# WKUP_CTRL_MMR0_CFG0 register map
Vendor: Texas Instruments
Registers are 32-bit, read-write, reset 0x0 unless marked. A register's access mark holds for its fields unless they carry their own. Offsets are as the file gives them; [hi:lo] are bit positions; {n}, {i} and the like mark numbered series.

## WKUP_CTRL_MMR0_CFG0 (part 2 of 11)
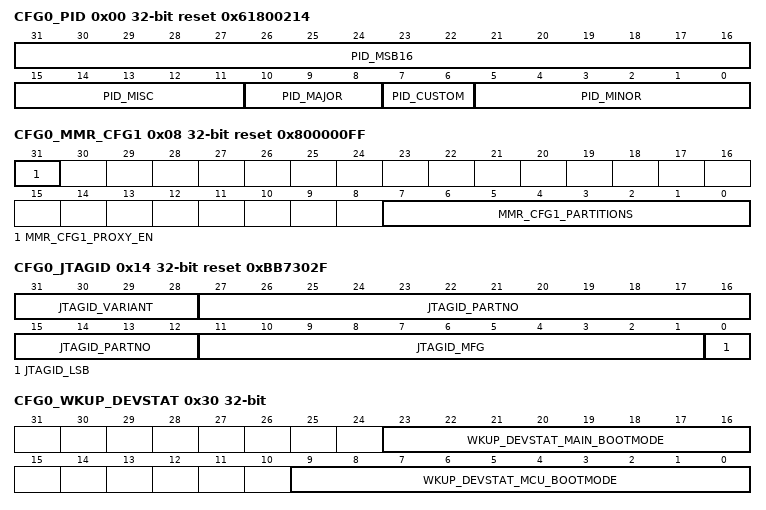
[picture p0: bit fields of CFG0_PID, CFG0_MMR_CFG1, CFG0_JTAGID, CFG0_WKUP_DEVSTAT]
0x00 CFG0_PID ro reset 0x61800214 — Peripheral release details
  [31:16] PID_MSB16
  [15:11] PID_MISC
  [10:8] PID_MAJOR
  [7:6] PID_CUSTOM — Custom revision number - actual value determined by RTL
  [5:0] PID_MINOR
0x08 CFG0_MMR_CFG1 ro reset 0x800000FF — Indicates the MMR configuration
  [31] MMR_CFG1_PROXY_EN — Proxy addressing enabled
  [7:0] MMR_CFG1_PARTITIONS — Indicates present partitions
0x14 CFG0_JTAGID ro reset 0xBB7302F — The JTAGID register must be readable by the configuration bus so that this can be accessed via the JTAG and CPU. In Boundary Scan mode, this ID should also be readable with only TCLK present. This means without a valid CPU clock running and also implies that Fusefarm scan is not necessary. The partno and variant field inputs should be set in the top metal mask so that this may be changed if a future PG is necessary. All other fields may be hard coded.
  [31:28] JTAGID_VARIANT — Used to indicate new PGs
  [27:12] JTAGID_PARTNO — Part number for boundary scan
  [11:1] JTAGID_MFG — Indicates manufacturer
  [0] JTAGID_LSB — Always 1
{0x20+4i} CFG0_DIE_ID{i} ro (i=0..3) — Contains information to identify this particular die.
  [31:0] DIE_ID{i}_DIEID — Contains individual die information
0x30 CFG0_WKUP_DEVSTAT — Indicates MCU bootstrap selection. The default value of this register is determined by the MCU bootstrap pins when the por_boot_cfg_srst_n input is de-asserted.
  [23:16] WKUP_DEVSTAT_MAIN_BOOTMODE — Specifies the device Primary and Backup boot media.Bit assignments defined by ROM
  [9:0] WKUP_DEVSTAT_MCU_BOOTMODE — Indicates MCU boot mode. Bits 9:8 - Power-on Self Test mode (if POST_SEL_STAT = 0x0) 00 - POST mode 1 (See POST_OPT_opt1_xxx bitfields) 01 - POST mode 2 (See POST_OPT_opt2_xxx bitfields) 10 - POST mode 3 (See POST_OPT_opt3_xxx bitfields) 11 - Bypass POST Bits 7:3 - MCU primary and secondary boot source Bits 2:0 - HFOSC0 frequency selection 000 - 19.2 MHz 001 - 20.0 MHz 010 - 24.0 MHz 011 - 25.0 MHz 100 - 26.0 MHz 101 - 27.0 MHz 110 - Reserved for device test 111 - No PLL configuration
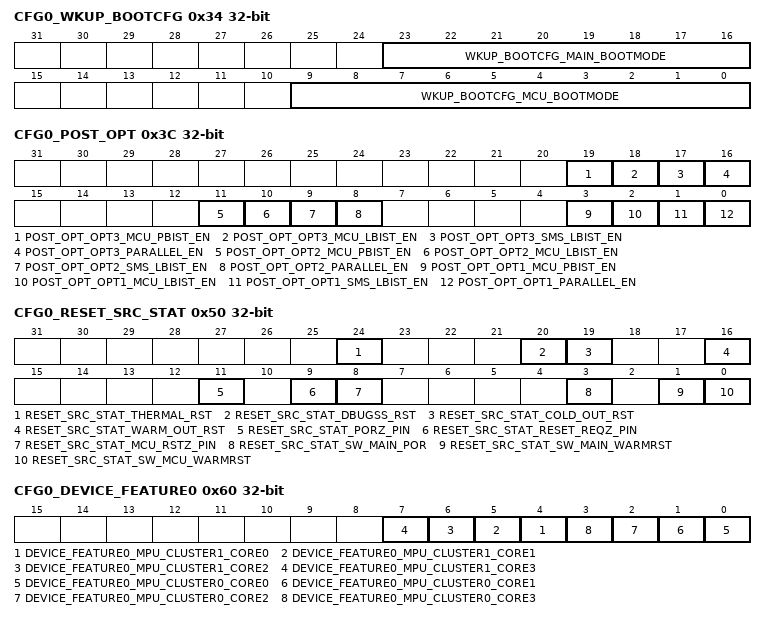
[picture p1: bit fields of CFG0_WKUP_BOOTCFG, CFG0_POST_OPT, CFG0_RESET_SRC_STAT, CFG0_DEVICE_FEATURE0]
0x34 CFG0_WKUP_BOOTCFG ro — Indicates MCU bootstrap selection latched at power-on reset by PORz. The default value of this register is determined by the MCU bootstrap pins when the por_boot_cfg_srst_n input is de-asserted and will remain until the MCU bootstrap pins are re-latched on a subsequent por_boot_cfg_srst_n rising edge.
  [23:16] WKUP_BOOTCFG_MAIN_BOOTMODE — Specifies the device Primary and Backup boot media as latched at PORzBit assignments assigned by ROM
  [9:0] WKUP_BOOTCFG_MCU_BOOTMODE — Indicates MCU boot mode as latched at power-on reset
0x38 CFG0_POST_SEL_STAT ro — Indicates which power-on self test option was performed.
  [1:0] POST_SEL_STAT_POST_SEL_STAT — Indicates which POST option was selected at power-up
0x3C CFG0_POST_OPT ro — Bits 19:16 - POST Option 3
  [19] POST_OPT_OPT3_MCU_PBIST_EN — MCU R5 PBIST enabled
  [18] POST_OPT_OPT3_MCU_LBIST_EN — MCU R5 LBIST enabled
  [17] POST_OPT_OPT3_SMS_LBIST_EN — SMS LBIST enabled
  [16] POST_OPT_OPT3_PARALLEL_EN — Selects SMS/MCU R5 LBIST sequencing 0 - Serial (SMS LBIST performed first) 1 - Parallel
  [11] POST_OPT_OPT2_MCU_PBIST_EN — MCU R5 PBIST enabled
  [10] POST_OPT_OPT2_MCU_LBIST_EN — MCU R5 LBIST enabled
  [9] POST_OPT_OPT2_SMS_LBIST_EN — SMS LBIST enabled
  [8] POST_OPT_OPT2_PARALLEL_EN — Selects SMS/MCU R5 LBIST sequencing 0 - Serial (SMS LBIST performed first) 1 - Parallel
  [3] POST_OPT_OPT1_MCU_PBIST_EN — MCU R5 PBIST enabled
  [2] POST_OPT_OPT1_MCU_LBIST_EN — MCU R5 LBIST enabled
  [1] POST_OPT_OPT1_SMS_LBIST_EN — SMS LBIST enabled
  [0] POST_OPT_OPT1_PARALLEL_EN — Selects SMS/MCU R5 LBIST sequencing 0 - Serial (SMS LBIST performed first) 1 - Parallel
0x44 CFG0_BOOT_PROGRESS — Used by ROM to mark the progress of the boot operation
  [31:0] BOOT_PROGRESS_PROGRESS — Written by ROM to indicate boot progression. Values and their meaning are determined by the ROM.
0x50 CFG0_RESET_SRC_STAT — Indicates sosurce of last device reset
  [24] RESET_SRC_STAT_THERMAL_RST — When set, indicates that a VTM Max Temp Thermal reset occurred.Write 1 to clear this bit.
  [20] RESET_SRC_STAT_DBUGSS_RST — When set, indicates that a Debug reset occurred.Write 1 to clear this bit.
  [19] RESET_SRC_STAT_COLD_OUT_RST — When set, indicates that a SMS Cold reset occurred.Write 1 to clear this bit.
  [16] RESET_SRC_STAT_WARM_OUT_RST — When set, indicates that a SMS Warm reset occurred.Write 1 to clear this bit.
  [11] RESET_SRC_STAT_PORZ_PIN — When set indicates that a PORz pin reset occurred.Write 1 to clear this bit.
  [9] RESET_SRC_STAT_RESET_REQZ_PIN — When set indicates that a RESET_REQz pin reset occurred.Write 1 to clear this bit.
  [8] RESET_SRC_STAT_MCU_RSTZ_PIN — When set indicates that a MCU_RESETz pin reset occurred.Write 1 to clear this bit.
  [3] RESET_SRC_STAT_SW_MAIN_POR — When set, indicates that a Software MAIN Power-on reset occurred.Write 1 to clear this bit.
  [1] RESET_SRC_STAT_SW_MAIN_WARMRST — When set indicates that a Software MAIN Warm reset occurred.Write 1 to clear this bit.
  [0] RESET_SRC_STAT_SW_MCU_WARMRST — When set indicates that a Software MCU Warm reset occurred.Write 1 to clear this bit.
0x60 CFG0_DEVICE_FEATURE0 ro — Indicates enabled MPU processing elements on the device
  [n+4] DEVICE_FEATURE0_MPU_CLUSTER1_CORE{n} (n=0..3) — MPU Cluster1 Core {n} is enabled when set
  [n] DEVICE_FEATURE0_MPU_CLUSTER0_CORE{n} (n=0..3) — MPU Cluster0 Core {n} is enabled when set
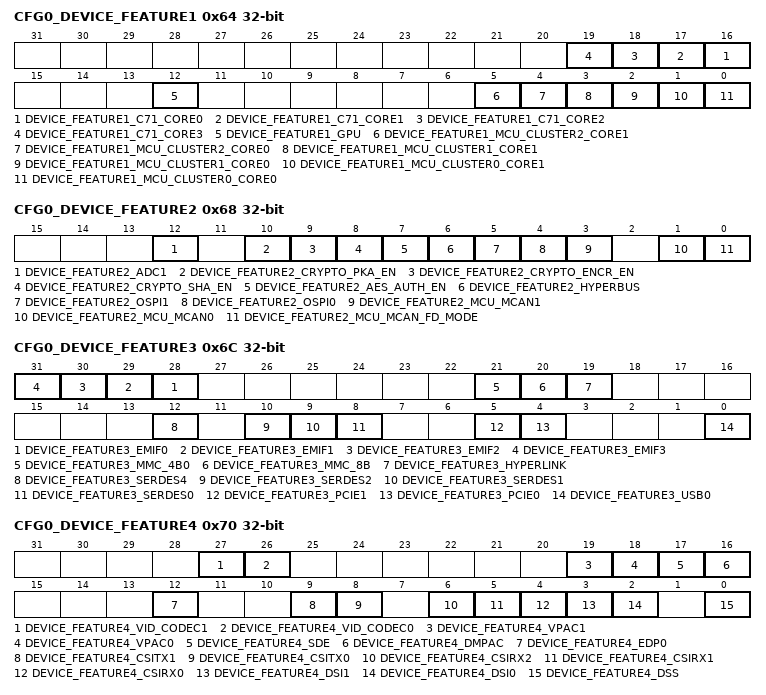
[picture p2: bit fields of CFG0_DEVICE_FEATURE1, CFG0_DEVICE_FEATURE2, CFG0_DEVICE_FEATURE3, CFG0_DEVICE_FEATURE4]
0x64 CFG0_DEVICE_FEATURE1 ro — Indicates enabled non-MPU processing elements on the device
  [n+16] DEVICE_FEATURE1_C71_CORE{n} (n=0..3) — C71 Core{n} is enabled when set
  [12] DEVICE_FEATURE1_GPU — GPU is enabled when set
  [5] DEVICE_FEATURE1_MCU_CLUSTER2_CORE1 — MAIN MCU Cluster2 Core1 is enabled when set
  [4] DEVICE_FEATURE1_MCU_CLUSTER2_CORE0 — MAIN MCU Cluster2 Core0 is enabled when set
  [3] DEVICE_FEATURE1_MCU_CLUSTER1_CORE1 — MAIN MCU Cluster1 Core1 is enabled when set
  [2] DEVICE_FEATURE1_MCU_CLUSTER1_CORE0 — MAIN MCU Cluster1 Core0 is enabled when set
  [1] DEVICE_FEATURE1_MCU_CLUSTER0_CORE1 — MAIN MCU Cluster0 Core1 is enabled when set
  [0] DEVICE_FEATURE1_MCU_CLUSTER0_CORE0 — MAIN MCU Cluster0 Core0 is enabled when set
0x68 CFG0_DEVICE_FEATURE2 ro — Indicates enabled MCU domain interface elements on the device
  [12] DEVICE_FEATURE2_ADC1 — MCU ADC1 is enabled when set
  [10] DEVICE_FEATURE2_CRYPTO_PKA_EN — MCU SA2_UL Crypto Module PKA enabled
  [9] DEVICE_FEATURE2_CRYPTO_ENCR_EN — MCU SA2_UL Crypto Module AES/3DES/DBRG enabled
  [8] DEVICE_FEATURE2_CRYPTO_SHA_EN — MCU SA2_UL Crypto Module SHA/MD5 enabled
  [7] DEVICE_FEATURE2_AES_AUTH_EN — AES authentication is enabled in MCU_FlashSS and SMS when set
  [6] DEVICE_FEATURE2_HYPERBUS — MCU_Hyperbus is enabled when set
  [5] DEVICE_FEATURE2_OSPI1 — MCU_OSPI1 is enabled when set
  [4] DEVICE_FEATURE2_OSPI0 — MCU_OSPI0 is enabled when set
  [3] DEVICE_FEATURE2_MCU_MCAN1 — MCU_MCAN1 is enabled when set
  [1] DEVICE_FEATURE2_MCU_MCAN0 — MCU_MCAN0 is enabled when set
  [0] DEVICE_FEATURE2_MCU_MCAN_FD_MODE — FD mode is supported on MCU_MCAN[1:0] when set
0x6C CFG0_DEVICE_FEATURE3 ro — Indicates enabled MAIN domain interface elements on the device
  [n+28] DEVICE_FEATURE3_EMIF{n} (n=0..3) — EMIF{n} is enabled when set
  [21] DEVICE_FEATURE3_MMC_4B0 — 4-bit MMC/SD1 is enabled when set
  [20] DEVICE_FEATURE3_MMC_8B — 8-bit MMC/SD0 is enabled when set
  [19] DEVICE_FEATURE3_HYPERLINK — Hyperlink interface is enabled when set
  [12] DEVICE_FEATURE3_SERDES4 — Serdes4 is enabled when set
  [10] DEVICE_FEATURE3_SERDES2 — Serdes2 is enabled when set
  [9] DEVICE_FEATURE3_SERDES1 — Serdes1 is enabled when set
  [8] DEVICE_FEATURE3_SERDES0 — Serdes0 is enabled when set
  [5] DEVICE_FEATURE3_PCIE1 — PCIe1 is enabled when set
  [4] DEVICE_FEATURE3_PCIE0 — PCIe0 is enabled when set
  [0] DEVICE_FEATURE3_USB0 — USB0 is enabled when set
0x70 CFG0_DEVICE_FEATURE4 ro — Indicates enabled MAIN domain interface elements on the device
  [27] DEVICE_FEATURE4_VID_CODEC1 — Video encoder/decoder 1 is enabled when set
  [26] DEVICE_FEATURE4_VID_CODEC0 — Video encoder/decoder 0 is enabled when set
  [19] DEVICE_FEATURE4_VPAC1 — VPAC1 is enabled when set
  [18] DEVICE_FEATURE4_VPAC0 — VPAC0 is enabled when set
  [17] DEVICE_FEATURE4_SDE — DMPAC Stereo Disparity Engine is enabled when set
  [16] DEVICE_FEATURE4_DMPAC — DMPAC is enabled when set
  [12] DEVICE_FEATURE4_EDP0 — Embedded display port 0 is enabled when set
  [9] DEVICE_FEATURE4_CSITX1 — CSI_TX1 is enabled when set
  [8] DEVICE_FEATURE4_CSITX0 — CSI_TX0 is enabled when set
  [6] DEVICE_FEATURE4_CSIRX2 — CSI_RX2 is enabled when set
  [5] DEVICE_FEATURE4_CSIRX1 — CSI_RX1 is enabled when set
  [4] DEVICE_FEATURE4_CSIRX0 — CSI_RX0 is enabled when set
  [3] DEVICE_FEATURE4_DSI1 — DSI1 is enabled when set
  [2] DEVICE_FEATURE4_DSI0 — DSI0 is enabled when set
  [0] DEVICE_FEATURE4_DSS — DSS is enabled when set
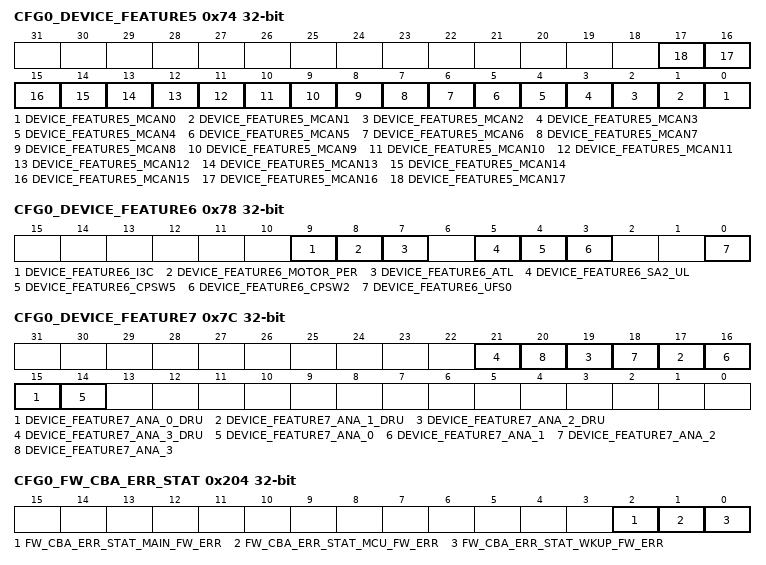
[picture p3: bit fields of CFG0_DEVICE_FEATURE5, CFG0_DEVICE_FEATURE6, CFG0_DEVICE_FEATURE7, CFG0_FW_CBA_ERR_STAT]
0x74 CFG0_DEVICE_FEATURE5 ro — Indicates enabled MAIN domain interface elements on the device
  [n] DEVICE_FEATURE5_MCAN{n} (n=0..17) — MCAN{n} is enabled when set
0x78 CFG0_DEVICE_FEATURE6 ro — Indicates enabled MAIN domain interface elements on the device
  [9] DEVICE_FEATURE6_I3C — MAIN domain I3C is enabled when set
  [8] DEVICE_FEATURE6_MOTOR_PER — Motor control peripherals (eCAP, eQEP, eHRPWM) are enabled when set
  [7] DEVICE_FEATURE6_ATL — Audio tracking logic is enabled when set
  [5] DEVICE_FEATURE6_SA2_UL — MAIN domain security accelerator is enabled when set
  [4] DEVICE_FEATURE6_CPSW5 — 8 Channel Q/SGMII Ethernet switch enabled when set
  [3] DEVICE_FEATURE6_CPSW2 — 1 Channel Ethernet switch enabled when set
  [0] DEVICE_FEATURE6_UFS0 — UFS interface 0 is enabled when set
0x7C CFG0_DEVICE_FEATURE7 ro — Indicates enabled MAIN domain bolt-on interface elements on the device
  [2n+15] DEVICE_FEATURE7_ANA_{n}_DRU (n=0..3) — Analytics {n} DRU is enabled when set
  [2n+14] DEVICE_FEATURE7_ANA_{n} (n=0..3) — Analytics {n} block is enabled when set
0x200 CFG0_DBG_CBA_ERR_STAT ro — Indicates addressing errors on the Debug CBA bus segments
  [1] DBG_CBA_ERR_STAT_MAIN_DBG_ERR — Main Debug bus segment error
0x204 CFG0_FW_CBA_ERR_STAT ro — Indicates addressing errors on the Firewall CBA bus segments
  [2] FW_CBA_ERR_STAT_MAIN_FW_ERR — MAIN Firewall bus segment error
  [1] FW_CBA_ERR_STAT_MCU_FW_ERR — MCU Firewall bus segment error
  [0] FW_CBA_ERR_STAT_WKUP_FW_ERR — WKUP Firewall bus segment error
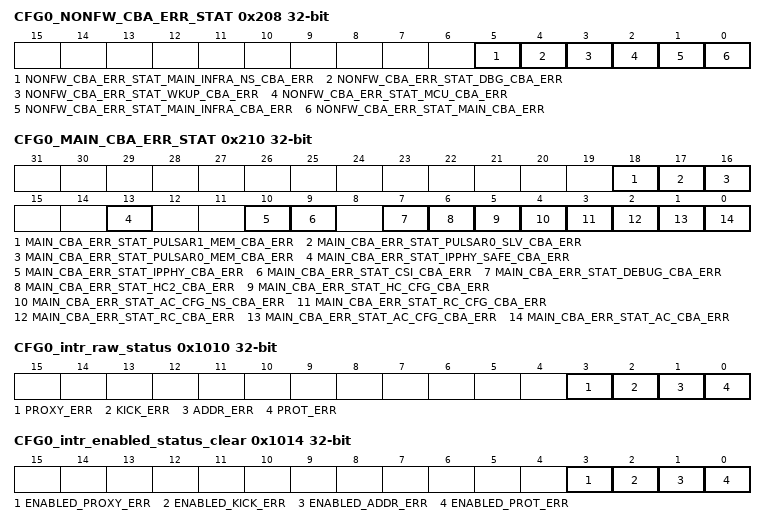
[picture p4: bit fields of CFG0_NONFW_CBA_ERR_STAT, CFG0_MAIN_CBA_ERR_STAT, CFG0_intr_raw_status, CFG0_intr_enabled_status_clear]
0x208 CFG0_NONFW_CBA_ERR_STAT ro — Indicates addressing errors on Non-Firewall CBA bus segments
  [5] NONFW_CBA_ERR_STAT_MAIN_INFRA_NS_CBA_ERR — MAIN Infrastructure non-safe bus segment error
  [4] NONFW_CBA_ERR_STAT_DBG_CBA_ERR — Debug bus aggregated error. See DBG_CBA_ERR_STAT for specific segment information.
  [3] NONFW_CBA_ERR_STAT_WKUP_CBA_ERR — WKUP Data bus segment error
  [2] NONFW_CBA_ERR_STAT_MCU_CBA_ERR — MCU Data bus segment error
  [1] NONFW_CBA_ERR_STAT_MAIN_INFRA_CBA_ERR — MAIN Infrastructure safe bus segment error
  [0] NONFW_CBA_ERR_STAT_MAIN_CBA_ERR — MAIN Data bus aggregated error. See MAIN_CBA_ERR_STAT for specific segment information
0x210 CFG0_MAIN_CBA_ERR_STAT ro — Indicates addressing errors on the MAIN CBA bus segments
  [18] MAIN_CBA_ERR_STAT_PULSAR1_MEM_CBA_ERR — MAIN R5 Cluster 1 Memory Data bus segment error
  [17] MAIN_CBA_ERR_STAT_PULSAR0_SLV_CBA_ERR — MAIN R5 Cluster 0 Slave Data bus segment error
  [16] MAIN_CBA_ERR_STAT_PULSAR0_MEM_CBA_ERR — MAIN R5 Cluster 0 Memory Data bus segment error
  [13] MAIN_CBA_ERR_STAT_IPPHY_SAFE_CBA_ERR — MAIN Phy safe Data bus segment error
  [10] MAIN_CBA_ERR_STAT_IPPHY_CBA_ERR — MAIN Phy non-safe Data bus segment error
  [9] MAIN_CBA_ERR_STAT_CSI_CBA_ERR — MAIN CSI Data bus segment error
  [7] MAIN_CBA_ERR_STAT_DEBUG_CBA_ERR — MAIN Debug Data bus segment error
  [6] MAIN_CBA_ERR_STAT_HC2_CBA_ERR — MAIN HC2 Data bus segment error
  [5] MAIN_CBA_ERR_STAT_HC_CFG_CBA_ERR — MAIN HC CFG Data bus segment error
  [4] MAIN_CBA_ERR_STAT_AC_CFG_NS_CBA_ERR — MAIN AC non-safe CFG Data bus segment error
  [3] MAIN_CBA_ERR_STAT_RC_CFG_CBA_ERR — MAIN RC CFG Data bus segment error
  [2] MAIN_CBA_ERR_STAT_RC_CBA_ERR — MAIN RC Data bus segment error
  [1] MAIN_CBA_ERR_STAT_AC_CFG_CBA_ERR — MAIN AC CFG Data bus segment error
  [0] MAIN_CBA_ERR_STAT_AC_CBA_ERR — MAIN AC Data bus segment error
{0x1008+0x4000*i} CFG0_LOCK{i}_KICK0 (i=0..7) — This register must be written with the designated key value followed by a write to LOCK{i}_KICK1 with its key value before write-protected Partition {i} registers can be written.
  [31:0] LOCK{i}_KICK0 — - KICK0 component
{0x100C+0x4000*i} CFG0_LOCK{i}_KICK1 (i=0..7) — This register must be written with the designated key value after a write to LOCK{i}_KICK0 with its key value before write-protected Partition {i} registers can be written.
  [31:0] LOCK{i}_KICK1 — - KICK1 component
0x1010 CFG0_intr_raw_status access not given
  [3] PROXY_ERR — Proxy0 access violation error. Raw status is read. Write a 1 to set the status. Writing a 0 has no effect. (access R/W1TS)
  [2] KICK_ERR — Kick access violation error. Raw status is read. Write a 1 to set the status. Writing a 0 has no effect. (access R/W1TS)
  [1] ADDR_ERR — Addressing violation error. Raw status is read. Write a 1 to set the status. Writing a 0 has no effect. (access R/W1TS)
  [0] PROT_ERR — Protection violation error. Raw status is read. Write a 1 to set the status. Writing a 0 has no effect. (access R/W1TS)
0x1014 CFG0_intr_enabled_status_clear access not given
  [3] ENABLED_PROXY_ERR — Proxy0 access violation error. Enabled status is read. Write a 1 to clear the status. Writing a 0 has no effect. (access R/W1TC)
  [2] ENABLED_KICK_ERR — Kick access violation error. Enabled status is read. Write a 1 to clear the status. Writing a 0 has no effect. (access R/W1TC)
  [1] ENABLED_ADDR_ERR — Addressing violation error. Enabled status is read. Write a 1 to clear the status. Writing a 0 has no effect. (access R/W1TC)
  [0] ENABLED_PROT_ERR — Protection violation error. Enabled status is read. Write a 1 to clear the status. Writing a 0 has no effect. (access R/W1TC)
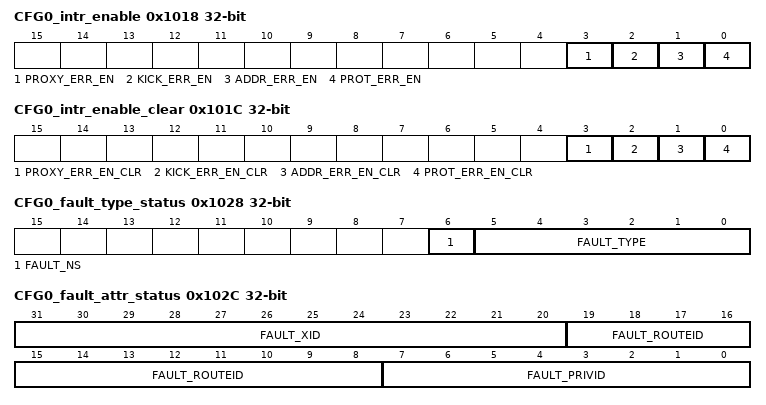
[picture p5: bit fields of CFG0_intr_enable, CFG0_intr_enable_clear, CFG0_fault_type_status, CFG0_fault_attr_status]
0x1018 CFG0_intr_enable access not given
  [3] PROXY_ERR_EN — Proxy0 access violation error enable. Write a 1 to set the enable. Writing a 0 has no effect. (access R/W1TS)
  [2] KICK_ERR_EN — Kick access violation error enable. Write a 1 to set the enable. Writing a 0 has no effect. (access R/W1TS)
  [1] ADDR_ERR_EN — Addressing violation error enable. Write a 1 to set the enable. Writing a 0 has no effect. (access R/W1TS)
  [0] PROT_ERR_EN — Protection violation error enable. Write a 1 to set the enable. Writing a 0 has no effect. (access R/W1TS)
0x101C CFG0_intr_enable_clear access not given
  [3] PROXY_ERR_EN_CLR — Proxy0 access violation error enable clear. Write a 1 to clear the enable. Writing a 0 has no effect. (access R/W1TC)
  [2] KICK_ERR_EN_CLR — Kick access violation error enable clear. Write a 1 to clear the enable. Writing a 0 has no effect. (access R/W1TC)
  [1] ADDR_ERR_EN_CLR — Addressing violation error enable clear. Write a 1 to clear the enable. Writing a 0 has no effect. (access R/W1TC)
  [0] PROT_ERR_EN_CLR — Protection violation error enable clear. Write a 1 to clear the enable. Writing a 0 has no effect. (access R/W1TC)
0x1020 CFG0_eoi — This register should be written with interrupt distribution value required by the device architecture to indicate service completion of the MMR interrupt. (See device specification for details)
  [7:0] EOI_VECTOR — EOI vector value. Write this with interrupt distribution value in the chip.
0x1024 CFG0_fault_address ro
  [31:0] FAULT_ADDR — Fault Address.
0x1028 CFG0_fault_type_status ro
  [6] FAULT_NS — Non-secure access.
  [5:0] FAULT_TYPE — Fault Type 10_0000 = Supervisor read fault - priv = 1 dir = 1 dtype != 1 01_0000 = Supervisor write fault - priv = 1 dir = 0 00_1000 = Supervisor execute fault - priv = 1 dir = 1 dtype = 1 00_0100 = User read fault - priv = 0 dir = 1 dtype = 1 00_0010 = User write fault - priv = 0 dir = 0 00_0001 = User execute fault - priv = 0 dir = 1 dtype = 1 00_0000 = No fault
0x102C CFG0_fault_attr_status ro
  [31:20] FAULT_XID — XID.
  [19:8] FAULT_ROUTEID — Route ID.
  [7:0] FAULT_PRIVID — Privilege ID.
0x1030 CFG0_fault_clear wo
  [0] FAULT_CLR — Fault clear. Writing a 1 clears the current fault. Writing a 0 has no effect.
{0x1100+4i} CFG0_CLAIMREG_P0_R{i}_READONLY ro (i=0..7)
  [31:0] CLAIMREG_P0_R{i}_READONLY — Claim bits for Partition 0
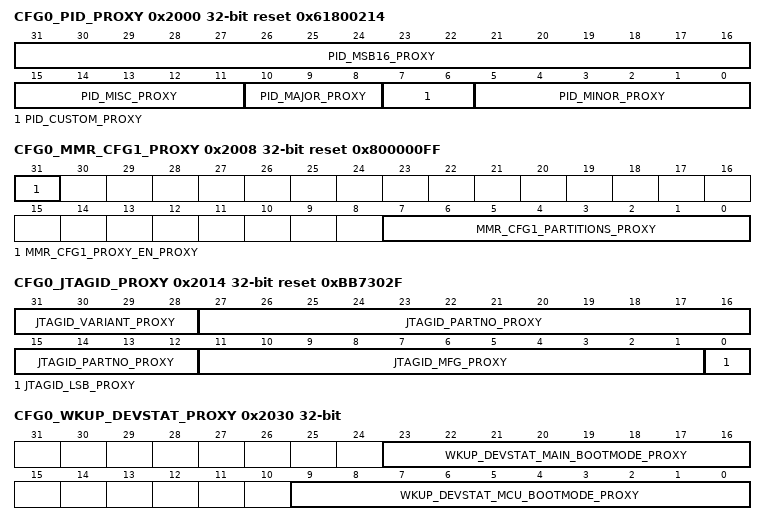
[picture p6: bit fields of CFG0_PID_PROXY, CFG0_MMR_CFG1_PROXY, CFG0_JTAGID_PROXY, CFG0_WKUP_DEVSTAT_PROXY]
0x2000 CFG0_PID_PROXY ro reset 0x61800214 — Peripheral release details
  [31:16] PID_MSB16_PROXY
  [15:11] PID_MISC_PROXY
  [10:8] PID_MAJOR_PROXY
  [7:6] PID_CUSTOM_PROXY — Custom revision number - actual value determined by RTL
  [5:0] PID_MINOR_PROXY
0x2008 CFG0_MMR_CFG1_PROXY ro reset 0x800000FF — Indicates the MMR configuration
  [31] MMR_CFG1_PROXY_EN_PROXY — Proxy addressing enabled
  [7:0] MMR_CFG1_PARTITIONS_PROXY — Indicates present partitions
0x2014 CFG0_JTAGID_PROXY ro reset 0xBB7302F — The JTAGID register must be readable by the configuration bus so that this can be accessed via the JTAG and CPU. In Boundary Scan mode, this ID should also be readable with only TCLK present. This means without a valid CPU clock running and also implies that Fusefarm scan is not necessary. The partno and variant field inputs should be set in the top metal mask so that this may be changed if a future PG is necessary. All other fields may be hard coded.
  [31:28] JTAGID_VARIANT_PROXY — Used to indicate new PGs
  [27:12] JTAGID_PARTNO_PROXY — Part number for boundary scan
  [11:1] JTAGID_MFG_PROXY — Indicates manufacturer
  [0] JTAGID_LSB_PROXY — Always 1
{0x2020+4i} CFG0_DIE_ID{i}_PROXY ro (i=0..3) — Contains information to identify this particular die.
  [31:0] DIE_ID{i}_DIEID_PROXY — Contains individual die information
0x2030 CFG0_WKUP_DEVSTAT_PROXY — Indicates MCU bootstrap selection. The default value of this register is determined by the MCU bootstrap pins when the por_boot_cfg_srst_n input is de-asserted.
  [23:16] WKUP_DEVSTAT_MAIN_BOOTMODE_PROXY — Specifies the device Primary and Backup boot media.Bit assignments defined by ROM
  [9:0] WKUP_DEVSTAT_MCU_BOOTMODE_PROXY — Indicates MCU boot mode. Bits 9:8 - Power-on Self Test mode (if POST_SEL_STAT = 0x0) 00 - POST mode 1 (See POST_OPT_opt1_xxx bitfields) 01 - POST mode 2 (See POST_OPT_opt2_xxx bitfields) 10 - POST mode 3 (See POST_OPT_opt3_xxx bitfields) 11 - Bypass POST Bits 7:3 - MCU primary and secondary boot source Bits 2:0 - HFOSC0 frequency selection 000 - 19.2 MHz 001 - 20.0 MHz 010 - 24.0 MHz 011 - 25.0 MHz 100 - 26.0 MHz 101 - 27.0 MHz 110 - Reserved for device test 111 - No PLL configuration
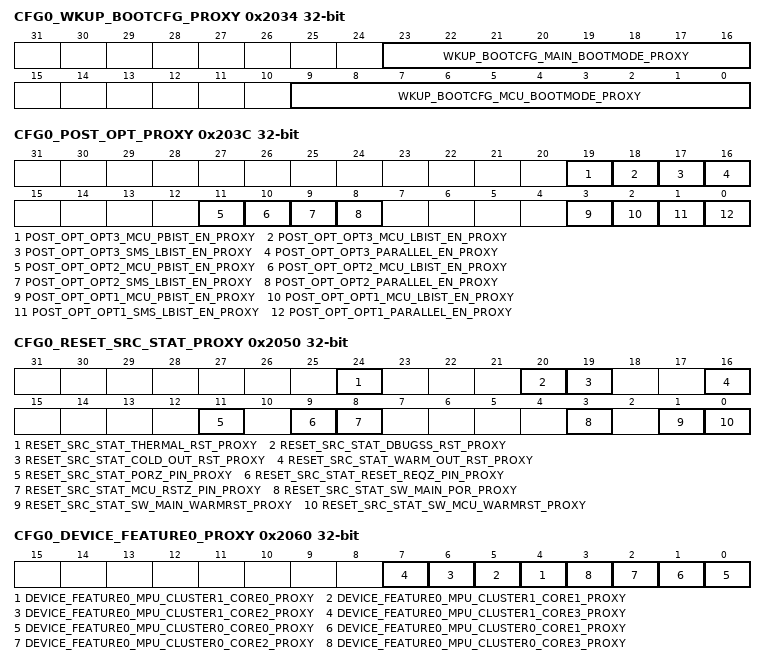
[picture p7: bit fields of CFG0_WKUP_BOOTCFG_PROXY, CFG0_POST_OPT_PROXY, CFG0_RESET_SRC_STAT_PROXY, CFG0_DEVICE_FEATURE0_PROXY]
0x2034 CFG0_WKUP_BOOTCFG_PROXY ro — Indicates MCU bootstrap selection latched at power-on reset by PORz. The default value of this register is determined by the MCU bootstrap pins when the por_boot_cfg_srst_n input is de-asserted and will remain until the MCU bootstrap pins are re-latched on a subsequent por_boot_cfg_srst_n rising edge.
  [23:16] WKUP_BOOTCFG_MAIN_BOOTMODE_PROXY — Specifies the device Primary and Backup boot media as latched at PORzBit assignments assigned by ROM
  [9:0] WKUP_BOOTCFG_MCU_BOOTMODE_PROXY — Indicates MCU boot mode as latched at power-on reset
0x2038 CFG0_POST_SEL_STAT_PROXY ro — Indicates which power-on self test option was performed.
  [1:0] POST_SEL_STAT_POST_SEL_STAT_PROXY — Indicates which POST option was selected at power-up
0x203C CFG0_POST_OPT_PROXY ro — Bits 19:16 - POST Option 3
  [19] POST_OPT_OPT3_MCU_PBIST_EN_PROXY — MCU R5 PBIST enabled
  [18] POST_OPT_OPT3_MCU_LBIST_EN_PROXY — MCU R5 LBIST enabled
  [17] POST_OPT_OPT3_SMS_LBIST_EN_PROXY — SMS LBIST enabled
  [16] POST_OPT_OPT3_PARALLEL_EN_PROXY — Selects SMS/MCU R5 LBIST sequencing 0 - Serial (SMS LBIST performed first) 1 - Parallel
  [11] POST_OPT_OPT2_MCU_PBIST_EN_PROXY — MCU R5 PBIST enabled
  [10] POST_OPT_OPT2_MCU_LBIST_EN_PROXY — MCU R5 LBIST enabled
  [9] POST_OPT_OPT2_SMS_LBIST_EN_PROXY — SMS LBIST enabled
  [8] POST_OPT_OPT2_PARALLEL_EN_PROXY — Selects SMS/MCU R5 LBIST sequencing 0 - Serial (SMS LBIST performed first) 1 - Parallel
  [3] POST_OPT_OPT1_MCU_PBIST_EN_PROXY — MCU R5 PBIST enabled
  [2] POST_OPT_OPT1_MCU_LBIST_EN_PROXY — MCU R5 LBIST enabled
  [1] POST_OPT_OPT1_SMS_LBIST_EN_PROXY — SMS LBIST enabled
  [0] POST_OPT_OPT1_PARALLEL_EN_PROXY — Selects SMS/MCU R5 LBIST sequencing 0 - Serial (SMS LBIST performed first) 1 - Parallel
0x2044 CFG0_BOOT_PROGRESS_PROXY — Used by ROM to mark the progress of the boot operation
  [31:0] BOOT_PROGRESS_PROGRESS_PROXY — Written by ROM to indicate boot progression. Values and their meaning are determined by the ROM.
0x2050 CFG0_RESET_SRC_STAT_PROXY — Indicates sosurce of last device reset
  [24] RESET_SRC_STAT_THERMAL_RST_PROXY — When set, indicates that a VTM Max Temp Thermal reset occurred.Write 1 to clear this bit.
  [20] RESET_SRC_STAT_DBUGSS_RST_PROXY — When set, indicates that a Debug reset occurred.Write 1 to clear this bit.
  [19] RESET_SRC_STAT_COLD_OUT_RST_PROXY — When set, indicates that a SMS Cold reset occurred.Write 1 to clear this bit.
  [16] RESET_SRC_STAT_WARM_OUT_RST_PROXY — When set, indicates that a SMS Warm reset occurred.Write 1 to clear this bit.
  [11] RESET_SRC_STAT_PORZ_PIN_PROXY — When set indicates that a PORz pin reset occurred.Write 1 to clear this bit.
  [9] RESET_SRC_STAT_RESET_REQZ_PIN_PROXY — When set indicates that a RESET_REQz pin reset occurred.Write 1 to clear this bit.
  [8] RESET_SRC_STAT_MCU_RSTZ_PIN_PROXY — When set indicates that a MCU_RESETz pin reset occurred.Write 1 to clear this bit.
  [3] RESET_SRC_STAT_SW_MAIN_POR_PROXY — When set, indicates that a Software MAIN Power-on reset occurred.Write 1 to clear this bit.
  [1] RESET_SRC_STAT_SW_MAIN_WARMRST_PROXY — When set indicates that a Software MAIN Warm reset occurred.Write 1 to clear this bit.
  [0] RESET_SRC_STAT_SW_MCU_WARMRST_PROXY — When set indicates that a Software MCU Warm reset occurred.Write 1 to clear this bit.
0x2060 CFG0_DEVICE_FEATURE0_PROXY ro — Indicates enabled MPU processing elements on the device
  [n+4] DEVICE_FEATURE0_MPU_CLUSTER1_CORE{n}_PROXY (n=0..3) — MPU Cluster1 Core {n} is enabled when set
  [n] DEVICE_FEATURE0_MPU_CLUSTER0_CORE{n}_PROXY (n=0..3) — MPU Cluster0 Core {n} is enabled when set
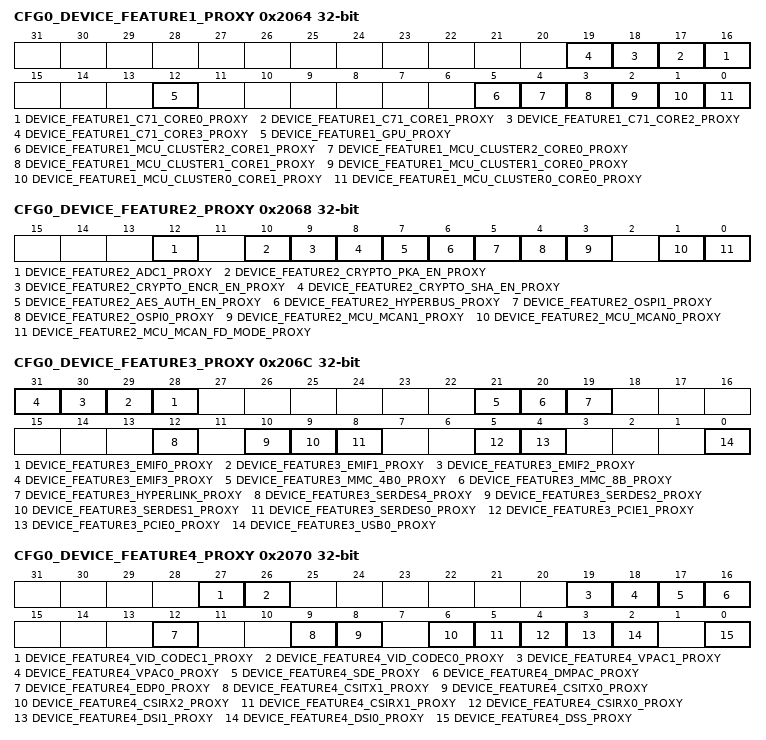
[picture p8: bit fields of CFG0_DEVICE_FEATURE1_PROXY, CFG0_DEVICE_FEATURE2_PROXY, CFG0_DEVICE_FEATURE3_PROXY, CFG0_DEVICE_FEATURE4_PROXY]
0x2064 CFG0_DEVICE_FEATURE1_PROXY ro — Indicates enabled non-MPU processing elements on the device
  [n+16] DEVICE_FEATURE1_C71_CORE{n}_PROXY (n=0..3) — C71 Core{n} is enabled when set
  [12] DEVICE_FEATURE1_GPU_PROXY — GPU is enabled when set
  [5] DEVICE_FEATURE1_MCU_CLUSTER2_CORE1_PROXY — MAIN MCU Cluster2 Core1 is enabled when set
  [4] DEVICE_FEATURE1_MCU_CLUSTER2_CORE0_PROXY — MAIN MCU Cluster2 Core0 is enabled when set
  [3] DEVICE_FEATURE1_MCU_CLUSTER1_CORE1_PROXY — MAIN MCU Cluster1 Core1 is enabled when set
  [2] DEVICE_FEATURE1_MCU_CLUSTER1_CORE0_PROXY — MAIN MCU Cluster1 Core0 is enabled when set
  [1] DEVICE_FEATURE1_MCU_CLUSTER0_CORE1_PROXY — MAIN MCU Cluster0 Core1 is enabled when set
  [0] DEVICE_FEATURE1_MCU_CLUSTER0_CORE0_PROXY — MAIN MCU Cluster0 Core0 is enabled when set
0x2068 CFG0_DEVICE_FEATURE2_PROXY ro — Indicates enabled MCU domain interface elements on the device
  [12] DEVICE_FEATURE2_ADC1_PROXY — MCU ADC1 is enabled when set
  [10] DEVICE_FEATURE2_CRYPTO_PKA_EN_PROXY — MCU SA2_UL Crypto Module PKA enabled
  [9] DEVICE_FEATURE2_CRYPTO_ENCR_EN_PROXY — MCU SA2_UL Crypto Module AES/3DES/DBRG enabled
  [8] DEVICE_FEATURE2_CRYPTO_SHA_EN_PROXY — MCU SA2_UL Crypto Module SHA/MD5 enabled
  [7] DEVICE_FEATURE2_AES_AUTH_EN_PROXY — AES authentication is enabled in MCU_FlashSS and SMS when set
  [6] DEVICE_FEATURE2_HYPERBUS_PROXY — MCU_Hyperbus is enabled when set
  [5] DEVICE_FEATURE2_OSPI1_PROXY — MCU_OSPI1 is enabled when set
  [4] DEVICE_FEATURE2_OSPI0_PROXY — MCU_OSPI0 is enabled when set
  [3] DEVICE_FEATURE2_MCU_MCAN1_PROXY — MCU_MCAN1 is enabled when set
  [1] DEVICE_FEATURE2_MCU_MCAN0_PROXY — MCU_MCAN0 is enabled when set
  [0] DEVICE_FEATURE2_MCU_MCAN_FD_MODE_PROXY — FD mode is supported on MCU_MCAN[1:0] when set
0x206C CFG0_DEVICE_FEATURE3_PROXY ro — Indicates enabled MAIN domain interface elements on the device
  [n+28] DEVICE_FEATURE3_EMIF{n}_PROXY (n=0..3) — EMIF{n} is enabled when set
  [21] DEVICE_FEATURE3_MMC_4B0_PROXY — 4-bit MMC/SD1 is enabled when set
  [20] DEVICE_FEATURE3_MMC_8B_PROXY — 8-bit MMC/SD0 is enabled when set
  [19] DEVICE_FEATURE3_HYPERLINK_PROXY — Hyperlink interface is enabled when set
  [12] DEVICE_FEATURE3_SERDES4_PROXY — Serdes4 is enabled when set
  [10] DEVICE_FEATURE3_SERDES2_PROXY — Serdes2 is enabled when set
  [9] DEVICE_FEATURE3_SERDES1_PROXY — Serdes1 is enabled when set
  [8] DEVICE_FEATURE3_SERDES0_PROXY — Serdes0 is enabled when set
  [5] DEVICE_FEATURE3_PCIE1_PROXY — PCIe1 is enabled when set
  [4] DEVICE_FEATURE3_PCIE0_PROXY — PCIe0 is enabled when set
  [0] DEVICE_FEATURE3_USB0_PROXY — USB0 is enabled when set
0x2070 CFG0_DEVICE_FEATURE4_PROXY ro — Indicates enabled MAIN domain interface elements on the device
  [27] DEVICE_FEATURE4_VID_CODEC1_PROXY — Video encoder/decoder 1 is enabled when set
  [26] DEVICE_FEATURE4_VID_CODEC0_PROXY — Video encoder/decoder 0 is enabled when set
  [19] DEVICE_FEATURE4_VPAC1_PROXY — VPAC1 is enabled when set
  [18] DEVICE_FEATURE4_VPAC0_PROXY — VPAC0 is enabled when set
  [17] DEVICE_FEATURE4_SDE_PROXY — DMPAC Stereo Disparity Engine is enabled when set
  [16] DEVICE_FEATURE4_DMPAC_PROXY — DMPAC is enabled when set
  [12] DEVICE_FEATURE4_EDP0_PROXY — Embedded display port 0 is enabled when set
  [9] DEVICE_FEATURE4_CSITX1_PROXY — CSI_TX1 is enabled when set
  [8] DEVICE_FEATURE4_CSITX0_PROXY — CSI_TX0 is enabled when set
  [6] DEVICE_FEATURE4_CSIRX2_PROXY — CSI_RX2 is enabled when set
  [5] DEVICE_FEATURE4_CSIRX1_PROXY — CSI_RX1 is enabled when set
  [4] DEVICE_FEATURE4_CSIRX0_PROXY — CSI_RX0 is enabled when set
  [3] DEVICE_FEATURE4_DSI1_PROXY — DSI1 is enabled when set
  [2] DEVICE_FEATURE4_DSI0_PROXY — DSI0 is enabled when set
  [0] DEVICE_FEATURE4_DSS_PROXY — DSS is enabled when set
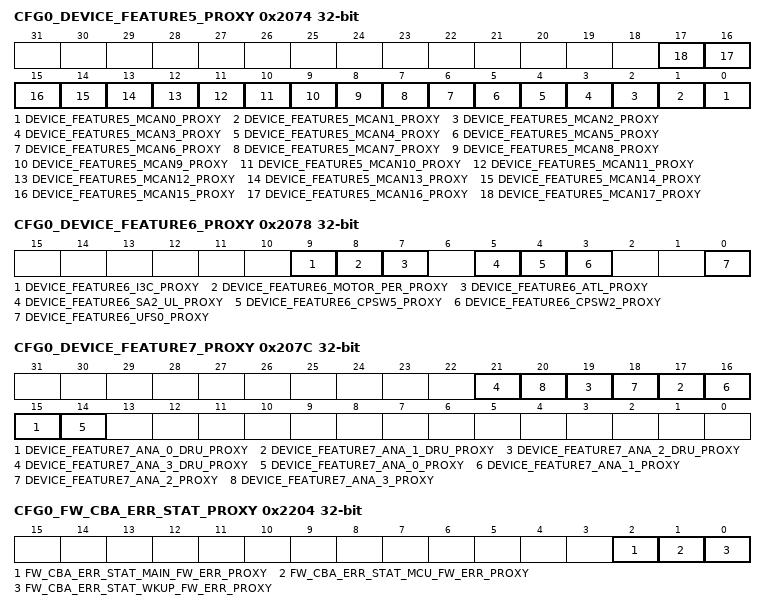
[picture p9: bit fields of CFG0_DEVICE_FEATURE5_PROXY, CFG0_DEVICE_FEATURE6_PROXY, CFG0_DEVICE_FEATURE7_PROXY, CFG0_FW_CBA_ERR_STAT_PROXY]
0x2074 CFG0_DEVICE_FEATURE5_PROXY ro — Indicates enabled MAIN domain interface elements on the device
  [n] DEVICE_FEATURE5_MCAN{n}_PROXY (n=0..17) — MCAN{n} is enabled when set
0x2078 CFG0_DEVICE_FEATURE6_PROXY ro — Indicates enabled MAIN domain interface elements on the device
  [9] DEVICE_FEATURE6_I3C_PROXY — MAIN domain I3C is enabled when set
  [8] DEVICE_FEATURE6_MOTOR_PER_PROXY — Motor control peripherals (eCAP, eQEP, eHRPWM) are enabled when set
  [7] DEVICE_FEATURE6_ATL_PROXY — Audio tracking logic is enabled when set
  [5] DEVICE_FEATURE6_SA2_UL_PROXY — MAIN domain security accelerator is enabled when set
  [4] DEVICE_FEATURE6_CPSW5_PROXY — 8 Channel Q/SGMII Ethernet switch enabled when set
  [3] DEVICE_FEATURE6_CPSW2_PROXY — 1 Channel Ethernet switch enabled when set
  [0] DEVICE_FEATURE6_UFS0_PROXY — UFS interface 0 is enabled when set
0x207C CFG0_DEVICE_FEATURE7_PROXY ro — Indicates enabled MAIN domain bolt-on interface elements on the device
  [2n+15] DEVICE_FEATURE7_ANA_{n}_DRU_PROXY (n=0..3) — Analytics {n} DRU is enabled when set
  [2n+14] DEVICE_FEATURE7_ANA_{n}_PROXY (n=0..3) — Analytics {n} block is enabled when set
0x2200 CFG0_DBG_CBA_ERR_STAT_PROXY ro — Indicates addressing errors on the Debug CBA bus segments
  [1] DBG_CBA_ERR_STAT_MAIN_DBG_ERR_PROXY — Main Debug bus segment error
0x2204 CFG0_FW_CBA_ERR_STAT_PROXY ro — Indicates addressing errors on the Firewall CBA bus segments
  [2] FW_CBA_ERR_STAT_MAIN_FW_ERR_PROXY — MAIN Firewall bus segment error
  [1] FW_CBA_ERR_STAT_MCU_FW_ERR_PROXY — MCU Firewall bus segment error
  [0] FW_CBA_ERR_STAT_WKUP_FW_ERR_PROXY — WKUP Firewall bus segment error
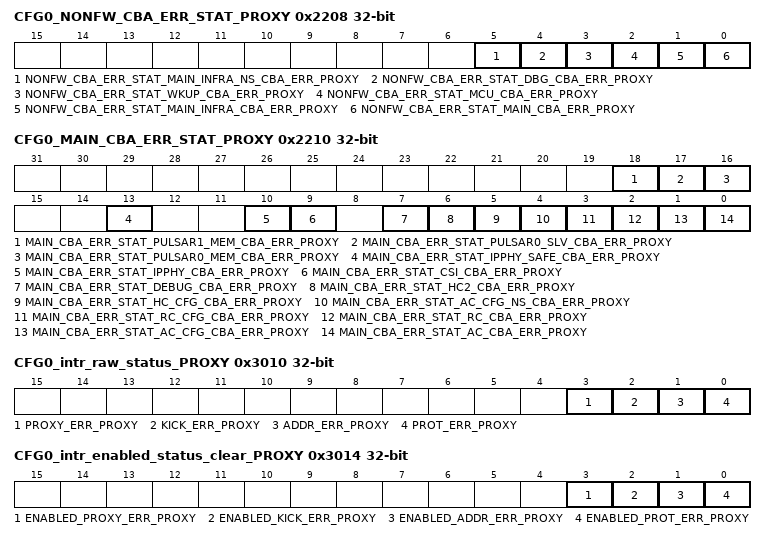
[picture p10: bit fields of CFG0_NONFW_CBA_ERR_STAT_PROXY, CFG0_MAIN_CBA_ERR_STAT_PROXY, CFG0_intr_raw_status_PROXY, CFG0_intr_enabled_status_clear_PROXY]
0x2208 CFG0_NONFW_CBA_ERR_STAT_PROXY ro — Indicates addressing errors on Non-Firewall CBA bus segments
  [5] NONFW_CBA_ERR_STAT_MAIN_INFRA_NS_CBA_ERR_PROXY — MAIN Infrastructure non-safe bus segment error
  [4] NONFW_CBA_ERR_STAT_DBG_CBA_ERR_PROXY — Debug bus aggregated error. See DBG_CBA_ERR_STAT for specific segment information.
  [3] NONFW_CBA_ERR_STAT_WKUP_CBA_ERR_PROXY — WKUP Data bus segment error
  [2] NONFW_CBA_ERR_STAT_MCU_CBA_ERR_PROXY — MCU Data bus segment error
  [1] NONFW_CBA_ERR_STAT_MAIN_INFRA_CBA_ERR_PROXY — MAIN Infrastructure safe bus segment error
  [0] NONFW_CBA_ERR_STAT_MAIN_CBA_ERR_PROXY — MAIN Data bus aggregated error. See MAIN_CBA_ERR_STAT for specific segment information
0x2210 CFG0_MAIN_CBA_ERR_STAT_PROXY ro — Indicates addressing errors on the MAIN CBA bus segments
  [18] MAIN_CBA_ERR_STAT_PULSAR1_MEM_CBA_ERR_PROXY — MAIN R5 Cluster 1 Memory Data bus segment error
  [17] MAIN_CBA_ERR_STAT_PULSAR0_SLV_CBA_ERR_PROXY — MAIN R5 Cluster 0 Slave Data bus segment error
  [16] MAIN_CBA_ERR_STAT_PULSAR0_MEM_CBA_ERR_PROXY — MAIN R5 Cluster 0 Memory Data bus segment error
  [13] MAIN_CBA_ERR_STAT_IPPHY_SAFE_CBA_ERR_PROXY — MAIN Phy safe Data bus segment error
  [10] MAIN_CBA_ERR_STAT_IPPHY_CBA_ERR_PROXY — MAIN Phy non-safe Data bus segment error
  [9] MAIN_CBA_ERR_STAT_CSI_CBA_ERR_PROXY — MAIN CSI Data bus segment error
  [7] MAIN_CBA_ERR_STAT_DEBUG_CBA_ERR_PROXY — MAIN Debug Data bus segment error
  [6] MAIN_CBA_ERR_STAT_HC2_CBA_ERR_PROXY — MAIN HC2 Data bus segment error
  [5] MAIN_CBA_ERR_STAT_HC_CFG_CBA_ERR_PROXY — MAIN HC CFG Data bus segment error
  [4] MAIN_CBA_ERR_STAT_AC_CFG_NS_CBA_ERR_PROXY — MAIN AC non-safe CFG Data bus segment error
  [3] MAIN_CBA_ERR_STAT_RC_CFG_CBA_ERR_PROXY — MAIN RC CFG Data bus segment error
  [2] MAIN_CBA_ERR_STAT_RC_CBA_ERR_PROXY — MAIN RC Data bus segment error
  [1] MAIN_CBA_ERR_STAT_AC_CFG_CBA_ERR_PROXY — MAIN AC CFG Data bus segment error
  [0] MAIN_CBA_ERR_STAT_AC_CBA_ERR_PROXY — MAIN AC Data bus segment error
{0x3008+0x4000*i} CFG0_LOCK{i}_KICK0_PROXY (i=0..7) — This register must be written with the designated key value followed by a write to LOCK{i}_KICK1 with its key value before write-protected Partition {i} registers can be written.
  [31:0] LOCK{i}_KICK0_PROXY — - KICK0 component
{0x300C+0x4000*i} CFG0_LOCK{i}_KICK1_PROXY (i=0..7) — This register must be written with the designated key value after a write to LOCK{i}_KICK0 with its key value before write-protected Partition {i} registers can be written.
  [31:0] LOCK{i}_KICK1_PROXY — - KICK1 component
0x3010 CFG0_intr_raw_status_PROXY access not given
  [3] PROXY_ERR_PROXY — Proxy0 access violation error. Raw status is read. Write a 1 to set the status. Writing a 0 has no effect. (access R/W1TS)
  [2] KICK_ERR_PROXY — Kick access violation error. Raw status is read. Write a 1 to set the status. Writing a 0 has no effect. (access R/W1TS)
  [1] ADDR_ERR_PROXY — Addressing violation error. Raw status is read. Write a 1 to set the status. Writing a 0 has no effect. (access R/W1TS)
  [0] PROT_ERR_PROXY — Protection violation error. Raw status is read. Write a 1 to set the status. Writing a 0 has no effect. (access R/W1TS)
0x3014 CFG0_intr_enabled_status_clear_PROXY access not given
  [3] ENABLED_PROXY_ERR_PROXY — Proxy0 access violation error. Enabled status is read. Write a 1 to clear the status. Writing a 0 has no effect. (access R/W1TC)
  [2] ENABLED_KICK_ERR_PROXY — Kick access violation error. Enabled status is read. Write a 1 to clear the status. Writing a 0 has no effect. (access R/W1TC)
  [1] ENABLED_ADDR_ERR_PROXY — Addressing violation error. Enabled status is read. Write a 1 to clear the status. Writing a 0 has no effect. (access R/W1TC)
  [0] ENABLED_PROT_ERR_PROXY — Protection violation error. Enabled status is read. Write a 1 to clear the status. Writing a 0 has no effect. (access R/W1TC)
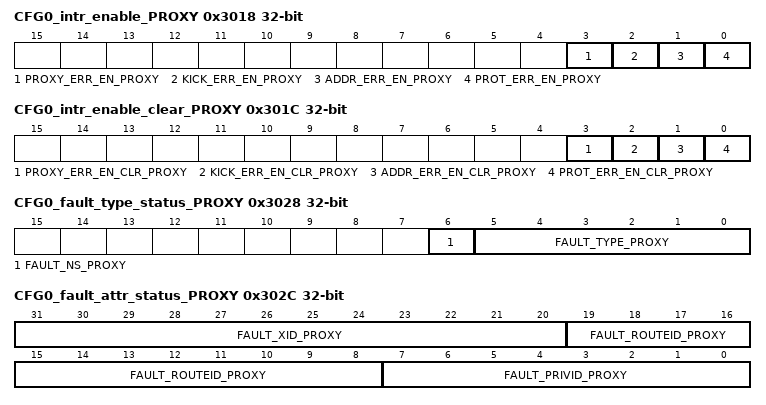
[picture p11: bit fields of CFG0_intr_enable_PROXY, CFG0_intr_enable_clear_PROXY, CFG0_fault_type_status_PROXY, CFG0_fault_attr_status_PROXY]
0x3018 CFG0_intr_enable_PROXY access not given
  [3] PROXY_ERR_EN_PROXY — Proxy0 access violation error enable. Write a 1 to set the enable. Writing a 0 has no effect. (access R/W1TS)
  [2] KICK_ERR_EN_PROXY — Kick access violation error enable. Write a 1 to set the enable. Writing a 0 has no effect. (access R/W1TS)
  [1] ADDR_ERR_EN_PROXY — Addressing violation error enable. Write a 1 to set the enable. Writing a 0 has no effect. (access R/W1TS)
  [0] PROT_ERR_EN_PROXY — Protection violation error enable. Write a 1 to set the enable. Writing a 0 has no effect. (access R/W1TS)
0x301C CFG0_intr_enable_clear_PROXY access not given
  [3] PROXY_ERR_EN_CLR_PROXY — Proxy0 access violation error enable clear. Write a 1 to clear the enable. Writing a 0 has no effect. (access R/W1TC)
  [2] KICK_ERR_EN_CLR_PROXY — Kick access violation error enable clear. Write a 1 to clear the enable. Writing a 0 has no effect. (access R/W1TC)
  [1] ADDR_ERR_EN_CLR_PROXY — Addressing violation error enable clear. Write a 1 to clear the enable. Writing a 0 has no effect. (access R/W1TC)
  [0] PROT_ERR_EN_CLR_PROXY — Protection violation error enable clear. Write a 1 to clear the enable. Writing a 0 has no effect. (access R/W1TC)
0x3020 CFG0_eoi_PROXY — This register should be written with interrupt distribution value required by the device architecture to indicate service completion of the MMR interrupt. (See device specification for details)
  [7:0] EOI_VECTOR_PROXY — EOI vector value. Write this with interrupt distribution value in the chip.
0x3024 CFG0_fault_address_PROXY ro
  [31:0] FAULT_ADDR_PROXY — Fault Address.
0x3028 CFG0_fault_type_status_PROXY ro
  [6] FAULT_NS_PROXY — Non-secure access.
  [5:0] FAULT_TYPE_PROXY — Fault Type 10_0000 = Supervisor read fault - priv = 1 dir = 1 dtype != 1 01_0000 = Supervisor write fault - priv = 1 dir = 0 00_1000 = Supervisor execute fault - priv = 1 dir = 1 dtype = 1 00_0100 = User read fault - priv = 0 dir = 1 dtype = 1 00_0010 = User write fault - priv = 0 dir = 0 00_0001 = User execute fault - priv = 0 dir = 1 dtype = 1 00_0000 = No fault
0x302C CFG0_fault_attr_status_PROXY ro
  [31:20] FAULT_XID_PROXY — XID.
  [19:8] FAULT_ROUTEID_PROXY — Route ID.
  [7:0] FAULT_PRIVID_PROXY — Privilege ID.
0x3030 CFG0_fault_clear_PROXY wo
  [0] FAULT_CLR_PROXY — Fault clear. Writing a 1 clears the current fault. Writing a 0 has no effect.
{0x3100+4i} CFG0_CLAIMREG_P0_R{i} (i=0..7)
  [31:0] CLAIMREG_P0_R{i} — Claim bits for Partition 0
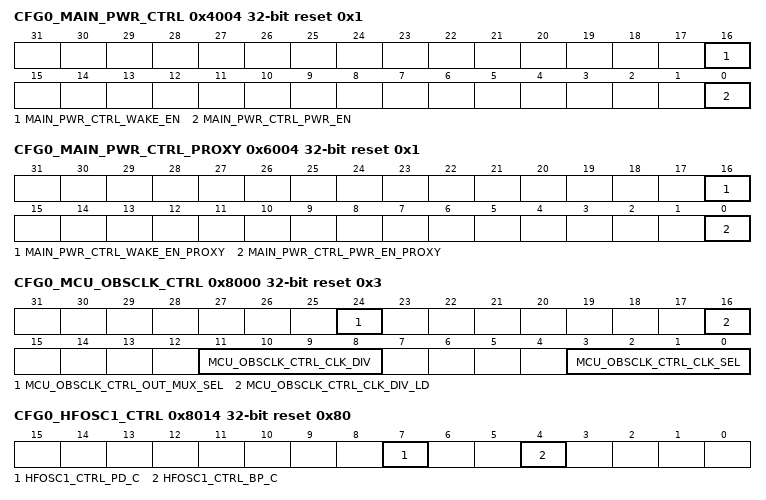
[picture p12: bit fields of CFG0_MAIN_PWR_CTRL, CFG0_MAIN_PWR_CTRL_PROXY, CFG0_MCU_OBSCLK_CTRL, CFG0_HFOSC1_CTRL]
0x4004 CFG0_MAIN_PWR_CTRL reset 0x1 — Controls power options for the MAIN voltage domain
  [16] MAIN_PWR_CTRL_WAKE_EN — When set, drives the PMIC_WAKE0 output (low). This bit should be set to 1'b1 only for diagnostic purposes. 0 - PMIC_WAKE0 output is tri-stated (controlled by IO daisy-chain wakeup) 1 - Force PMIC_WAKE0 output enable (PMIC_WAKE0 driven low)
  [0] MAIN_PWR_CTRL_PWR_EN — When set, drives the PMIC_PWR_EN1 output to turn on the MAIN voltage domain
0x4008 CFG0_MCU_PWR_CTRL — Controls power options for the MAIN voltage domain
  [16] MCU_PWR_CTRL_WAKE_EN — When set, drives the PMIC_WAKE1 output (low).This bit should be set to 1'b1 only for diagnostic purposes. 0 - PMIC_WAKE1 output is tri-stated (controlled by IO daisy-chain wakeup) 1 - Force PMIC_WAKE1 output enable (PMIC_WAKE1 driven low)
0x4020 CFG0_WKUP_GPIO_CTRL — Controls operation of the WKUP_GPIO module
  [0] WKUP_GPIO_CTRL_WAKEN — Enables WKUP_GPIO wakeup event operation by controlling the WKUP_GPIO LPSC clockstop_ack behavior. 1'b0 - No WKUP_GPIO wakeup support. WKUP_GPIO vbus clock is gated on LPSC clkstop_req. Field values (Others are reserved): 1'b0 - No WKUP_GPIO wakeup support. WKUP_GPIO vbus clock is gated on clkstop_ack from WKUP_GPIO to LPSC 1'b1 - WKUP_GPIO wakeup enabled. WKUP_GPIO vbus clock is NOT gated on LPSC clockstop_req. WKUP_GPIO LPSC clkstop_ack input is driven by clkstop_req output.
0x4030 CFG0_WKUP_I2C0_CTRL — Controls WKUP_I2C0 operation
  [0] WKUP_I2C0_CTRL_HS_MCS_EN — HS Mode master current source enable.When set, enables the current-source pull-up on the SCL output. Only one master on the I2C bus should enable SCL current sourcing.
{0x4080+4i} CFG0_DBOUNCE_CFG{i} (i=1..6) — Configures IO debounce selections
  [5:0] DBOUNCE_CFG{i}_DB_CFG — Configures the debounce period used for I/Os with debounce_sel{i} enabled. See the J7 IO Integration Spec for details.
{0x5100+4i} CFG0_CLAIMREG_P1_R{i}_READONLY ro (i=0..2)
  [31:0] CLAIMREG_P1_R{i}_READONLY — Claim bits for Partition 1
0x6004 CFG0_MAIN_PWR_CTRL_PROXY reset 0x1 — Controls power options for the MAIN voltage domain
  [16] MAIN_PWR_CTRL_WAKE_EN_PROXY — When set, drives the PMIC_WAKE0 output (low). This bit should be set to 1'b1 only for diagnostic purposes. 0 - PMIC_WAKE0 output is tri-stated (controlled by IO daisy-chain wakeup) 1 - Force PMIC_WAKE0 output enable (PMIC_WAKE0 driven low)
  [0] MAIN_PWR_CTRL_PWR_EN_PROXY — When set, drives the PMIC_PWR_EN1 output to turn on the MAIN voltage domain
0x6008 CFG0_MCU_PWR_CTRL_PROXY — Controls power options for the MAIN voltage domain
  [16] MCU_PWR_CTRL_WAKE_EN_PROXY — When set, drives the PMIC_WAKE1 output (low).This bit should be set to 1'b1 only for diagnostic purposes. 0 - PMIC_WAKE1 output is tri-stated (controlled by IO daisy-chain wakeup) 1 - Force PMIC_WAKE1 output enable (PMIC_WAKE1 driven low)
0x6020 CFG0_WKUP_GPIO_CTRL_PROXY — Controls operation of the WKUP_GPIO module
  [0] WKUP_GPIO_CTRL_WAKEN_PROXY — Enables WKUP_GPIO wakeup event operation by controlling the WKUP_GPIO LPSC clockstop_ack behavior. 1'b0 - No WKUP_GPIO wakeup support. WKUP_GPIO vbus clock is gated on LPSC clkstop_req. Field values (Others are reserved): 1'b0 - No WKUP_GPIO wakeup support. WKUP_GPIO vbus clock is gated on clkstop_ack from WKUP_GPIO to LPSC 1'b1 - WKUP_GPIO wakeup enabled. WKUP_GPIO vbus clock is NOT gated on LPSC clockstop_req. WKUP_GPIO LPSC clkstop_ack input is driven by clkstop_req output.
0x6030 CFG0_WKUP_I2C0_CTRL_PROXY — Controls WKUP_I2C0 operation
  [0] WKUP_I2C0_CTRL_HS_MCS_EN_PROXY — HS Mode master current source enable.When set, enables the current-source pull-up on the SCL output. Only one master on the I2C bus should enable SCL current sourcing.
{0x6080+4i} CFG0_DBOUNCE_CFG{i}_PROXY (i=1..6) — Configures IO debounce selections
  [5:0] DBOUNCE_CFG{i}_DB_CFG_PROXY — Configures the debounce period used for I/Os with debounce_sel{i} enabled. See the J7 IO Integration Spec for details.
{0x7100+4i} CFG0_CLAIMREG_P1_R{i} (i=0..2)
  [31:0] CLAIMREG_P1_R{i} — Claim bits for Partition 1
0x8000 CFG0_MCU_OBSCLK_CTRL reset 0x3 — Controls which internal clock is made observable on the MCU_OBSCLK output pin
  [24] MCU_OBSCLK_CTRL_OUT_MUX_SEL — MCU_OBSCLK pin output mux selection.Note, when HFOSC0_CLK is selected (1'b1) the MCU_OBSCLK_CTRL_clk_sel field must be programmed to 4'b0001. 1'b0 - The output of the MCU_OBSCLK output divider is output on the pin 1'b1 - HFOSC0_CLK is output on the pin
  [16] MCU_OBSCLK_CTRL_CLK_DIV_LD — Load the output divider valueWriting 1 to this bit will generate a load pulse to load the OBSCLK divider value. This bit can be cleared but must not be set in the same write cycle in which the clk_div value is changed.
  [11:8] MCU_OBSCLK_CTRL_CLK_DIV — MCU_OBSCLK pin clock selection output dividerOutput clock is divided by clk_div+1
  [3:0] MCU_OBSCLK_CTRL_CLK_SEL — MCU_OBSCLK pin clock selection Field values (Others are reserved): 4'b0000 - CLK_12M_RC 4'b0001 - 0 4'b0010 - MCU_PLL0_HSDIV0_CLKOUT 4'b0011 - MCU_PLLCTL_OBSCLK 4'b0100 - MCU_PLL1_HSDIV1_CLKOUT 4'b0101 - MCU_PLL1_HSDIV2_CLKOUT 4'b0110 - MCU_PLL1_HSDIV3_CLKOUT 4'b0111 - MCU_PLL1_HSDIV4_CLKOUT 4'b1000 - MCU_PLL2_HSDIV0_CLKOUT 4'b1001 - CLK_32K 4'b1010 - MCU_PLL2_HSDIV1_CLKOUT 4'b1011 - MCU_PLL2_HSDIV2_CLKOUT 4'b1100 - MCU_PLL2_HSDIV3_CLKOUT 4'b1101 - MCU_PLL2_HSDIV4_CLKOUT 4'b1110 - HFOSC0_CLKOUT 4'b1111 - LFXOSC_CLKOUT
0x8014 CFG0_HFOSC1_CTRL reset 0x80 — Controls the operation of oscillator 1
  [7] HFOSC1_CTRL_PD_C — Oscillator powerdown control. When set, oscillator is disabled. Oscillator output is tristated if bp_c=0
  [4] HFOSC1_CTRL_BP_C — Oscillator bypass control. When set oscillator is in bypass mode
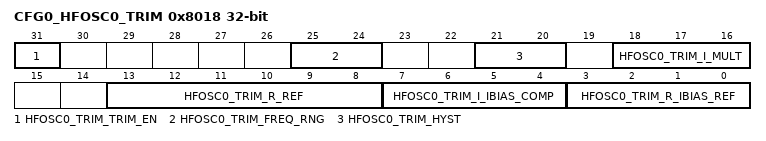
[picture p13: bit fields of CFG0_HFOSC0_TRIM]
0x8018 CFG0_HFOSC0_TRIM — Provides frequency trimming for oscillator 0
  [31] HFOSC0_TRIM_TRIM_EN — Apply MMR values to OSC trim inputs instead of tie-offs
  [25:24] HFOSC0_TRIM_FREQ_RNG — Sets the frequency range of operation based on:I(MIRRBIAS) = I(AGC) + 4x I(BIAS) (I(BIAS) : Bias current to AMP_AGC Block, I(AGC) : Current from AGC Loop and mirrored)
  [21:20] HFOSC0_TRIM_HYST — Sets comparator hysteresis
  [18:16] HFOSC0_TRIM_I_MULT — AGC AMP current multiplication gainI(MIRRBIAS) = I(AGC) + 4x I(BIAS) (I(BIAS) : Bias current to AMP_AGC Block, I(AGC) : Current from AGC Loop and mirrored)
  [13:8] HFOSC0_TRIM_R_REF — Sets the AMP AGC bias currentr_ref(5:3) are not used.
  [7:4] HFOSC0_TRIM_I_IBIAS_COMP — Sets the COMP bias currentx = 1 uA
  [3:0] HFOSC0_TRIM_R_IBIAS_REF — Sets the base IBIAS reference
